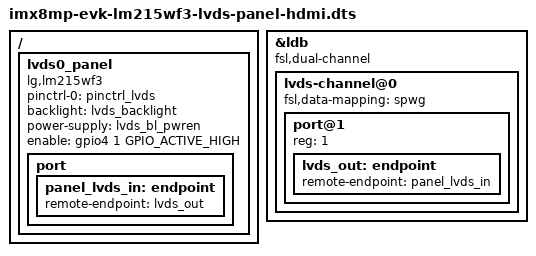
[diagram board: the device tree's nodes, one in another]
// SPDX-License-Identifier: GPL-2.0+
/*
 * Copyright 2020 NXP
 */

#include "imx8mp-evk.dts"

/ {
	lvds0_panel {
		compatible = "lg,lm215wf3";
		pinctrl-names = "default";
		pinctrl-0 = <&pinctrl_lvds>;
		backlight = <&lvds_backlight>;
		power-supply = <&lvds_bl_pwren>;
    enable = <&gpio4 1 GPIO_ACTIVE_HIGH >;
		port {
			panel_lvds_in: endpoint {
				remote-endpoint = <&lvds_out>;
			};
		};
	};
};

/delete-node/ &lvds_bridge;

&ldb {
	fsl,dual-channel;

	lvds-channel@0 {
		fsl,data-mapping = "spwg";

		/delete-node/ port@1;

		port@1 {
			reg = <1>;

			lvds_out: endpoint {
				remote-endpoint = <&panel_lvds_in>;
			};
		};
	};
};
